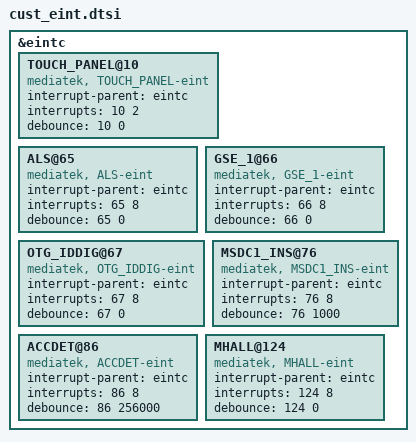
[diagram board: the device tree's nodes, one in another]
/*
 * Generated by MTK SP DrvGen Version 03.13.6 for MT6735M. Copyright MediaTek Inc. (C) 2013.
 * Wed Jun 10 15:25:28 2015
 * Do Not Modify the File.
 */

/*************************
 * EINT DTSI File
*************************/

&eintc {
	TOUCH_PANEL@10 {
		compatible = "mediatek, TOUCH_PANEL-eint";
		interrupt-parent = <&eintc>;
		interrupts = <10 2>;
		debounce = <10 0>;
	};

	ALS@65 {
		compatible = "mediatek, ALS-eint";
		interrupt-parent = <&eintc>;
		interrupts = <65 8>;
		debounce = <65 0>;
	};

	GSE_1@66 {
		compatible = "mediatek, GSE_1-eint";
		interrupt-parent = <&eintc>;
		interrupts = <66 8>;
		debounce = <66 0>;
	};

	OTG_IDDIG@67 {
		compatible = "mediatek, OTG_IDDIG-eint";
		interrupt-parent = <&eintc>;
		interrupts = <67 8>;
		debounce = <67 0>;
	};

	MSDC1_INS@76 {
		compatible = "mediatek, MSDC1_INS-eint";
		interrupt-parent = <&eintc>;
		interrupts = <76 8>;
		debounce = <76 1000>;
	};

	ACCDET@86 {
		compatible = "mediatek, ACCDET-eint";
		interrupt-parent = <&eintc>;
		interrupts = <86 8>;
		debounce = <86 256000>;
	};

	MHALL@124 {
		compatible = "mediatek, MHALL-eint";
		interrupt-parent = <&eintc>;
		interrupts = <124 8>;
		debounce = <124 0>;
	};

};
